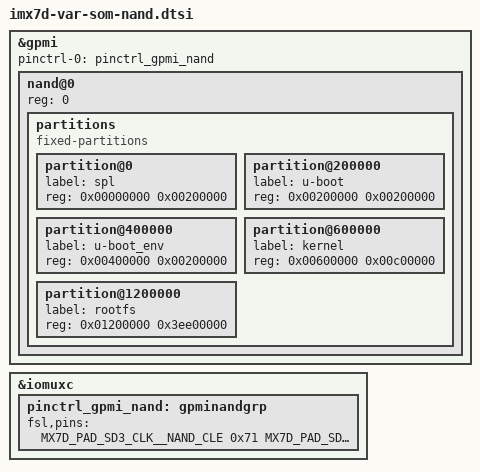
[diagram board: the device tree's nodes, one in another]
// SPDX-License-Identifier: (GPL-2.0+ OR MIT)
/*
 * Common dtsi for NAND support on Variscite VAR-SOM-MX7
 *
 * Link: https://variscite.com/system-on-module-som/i-mx-7/var-som-mx7/
 *
 * Copyright (C) 2026 Variscite Ltd. - https://www.variscite.com/
 *
 */

&gpmi {
	pinctrl-names = "default";
	pinctrl-0 = <&pinctrl_gpmi_nand>;
	status = "okay";

	nand@0 {
		reg = <0>;

		partitions {
			compatible = "fixed-partitions";
			#address-cells = <1>;
			#size-cells = <1>;

			partition@0 {
				label = "spl";
				reg = <0x00000000 0x00200000>;
			};

			partition@200000 {
				label = "u-boot";
				reg = <0x00200000 0x00200000>;
			};

			partition@400000 {
				label = "u-boot_env";
				reg = <0x00400000 0x00200000>;
			};

			partition@600000 {
				label = "kernel";
				reg = <0x00600000 0x00c00000>;
			};

			partition@1200000 {
				label = "rootfs";
				reg = <0x01200000 0x3ee00000>;
			};
		};
	};
};

&iomuxc {
	pinctrl_gpmi_nand: gpminandgrp {
		fsl,pins = <
			MX7D_PAD_SD3_CLK__NAND_CLE		0x71
			MX7D_PAD_SD3_CMD__NAND_ALE		0x71
			MX7D_PAD_SAI1_MCLK__NAND_WP_B		0x71
			MX7D_PAD_SAI1_TX_BCLK__NAND_CE0_B	0x71
			MX7D_PAD_SAI1_RX_DATA__NAND_CE1_B	0x71
			MX7D_PAD_SAI1_TX_DATA__NAND_READY_B	0x74
			MX7D_PAD_SD3_STROBE__NAND_RE_B		0x71
			MX7D_PAD_SD3_RESET_B__NAND_WE_B		0x71
			MX7D_PAD_SD3_DATA0__NAND_DATA00		0x71
			MX7D_PAD_SD3_DATA1__NAND_DATA01		0x71
			MX7D_PAD_SD3_DATA2__NAND_DATA02		0x71
			MX7D_PAD_SD3_DATA3__NAND_DATA03		0x71
			MX7D_PAD_SD3_DATA4__NAND_DATA04		0x71
			MX7D_PAD_SD3_DATA5__NAND_DATA05		0x71
			MX7D_PAD_SD3_DATA6__NAND_DATA06		0x71
			MX7D_PAD_SD3_DATA7__NAND_DATA07		0x71
		>;
	};
};
